# ADuCM302x register map
Vendor: Analog Devices; Series: ADuCM302x; File version: 1p0
CPU: CM3 r0p1, little endian, no MPU, no FPU, 3 interrupt priority bits
Registers are 32-bit, read-write, reset 0x0 unless marked. A register's access mark holds for its fields unless they carry their own. Offsets are from the block's base; [hi:lo] are bit positions; {n}, {i} and the like mark numbered series; <NAME> marks a mode.

## PMG0 — Power Management
Base 0x4004C000
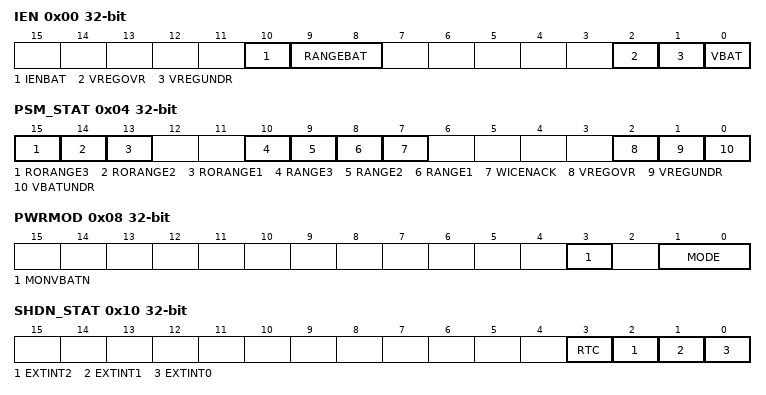
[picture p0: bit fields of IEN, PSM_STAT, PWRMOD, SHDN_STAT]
0x00 IEN — Power Supply Monitor Interrupt Enable
  [10] IENBAT range 0x00000000..0x00000001 — Interrupt Enable for VBAT Range
  [9:8] RANGEBAT — Battery Monitor Range
    0=region1 (Configure to generate interrupt if VBAT > 2.75 V); 1=region2 (Configure to generate interrupt if VBAT between 2.75 V - 1.6 V); 2=region3 (Configure to generate interrupt if VBAT between 2.3 V - 1.6 V); 3=NA
  [2] VREGOVR range 0x00000000..0x00000001 — Enable Interrupt When VREG Overvoltage: Above 1.32V
  [1] VREGUNDR range 0x00000000..0x00000001 — Enable Interrupt When VREG Undervoltage: Below 1V
  [0] VBAT range 0x00000000..0x00000001 — Enable Interrupt for VBAT
0x04 PSM_STAT — Power Supply Monitor Status
  [15] RORANGE3 ro — VBAT Range3 (2.3v - 1.6v)
  [14] RORANGE2 ro — VBAT Range2 (2.75v - 2.3v)
  [13] RORANGE1 ro — VBAT Range1 (> 2.75v)
    0=batstat1 (VBAT not in the range specified); 1=batstat0 (VBAT in the range specified)
  [10] RANGE3 — VBAT Range3 (2.3v - 1.6v)
  [9] RANGE2 — VBAT Range2 (2.75v - 2.3v)
  [8] RANGE1 — VBAT Range1 (> 2.75v)
  [7] WICENACK ro — WIC Enable Acknowledge from Cortex
  [2] VREGOVR range 0x00000000..0x00000001 — Status Bit for Alarm Indicating Overvoltage for VREG
  [1] VREGUNDR range 0x00000000..0x00000001 — Status Bit for Alarm Indicating VREG is Below 1V
  [0] VBATUNDR range 0x00000000..0x00000001 — Status Bit Indicating an Alarm That Battery is Below 1.8V
0x08 PWRMOD — Power Mode Register
  [3] MONVBATN — Monitor VBAT During Hibernate Mode. Monitors VBAT by Default
    0=VBAT_MONEN (VBAT monitor enabled in PMG block.); 1=VBAT_MONDIS (VBAT monitor disabled in PMG block.)
  [1:0] MODE — Power Mode Bits
    0=FLEXI (Flexi Mode); 2=HIBERNATE (Hibernate Mode); 3=SHUTDOWN (Shutdown Mode)
0x0C PWRKEY — Key Protection for PMG_PWRMOD and PMG_SRAMRET
  [15:0] VALUE wo range 0x00000000..0x0000FFFF — Power Control Key Register
0x10 SHDN_STAT — Shutdown Status Register
  [3] RTC ro — Wakeup by Interrupt from RTC
  [2] EXTINT2 ro — Wakeup by Interrupt from External Interrupt 2
  [1] EXTINT1 ro — Wakeup by Interrupt from External Interrupt 1
  [0] EXTINT0 ro — Wakeup by Interrupt from External Interrupt 0
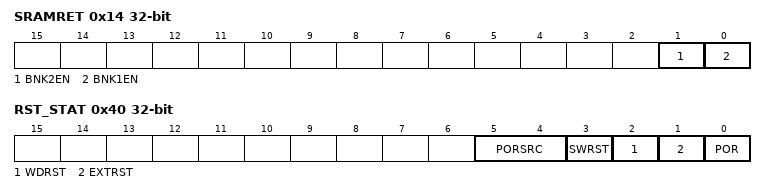
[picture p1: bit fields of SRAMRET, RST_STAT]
0x14 SRAMRET — Control for Retention SRAM in Hibernate Mode
  [1] BNK2EN range 0x00000000..0x00000001 — Enable Retention Bank 2 (16kB)
  [0] BNK1EN range 0x00000000..0x00000001 — Enable Retention Bank 1 (8kB)
0x40 RST_STAT — Reset Status
  [5:4] PORSRC ro — Power-on-Reset Source
    0=FAILSAFE_HV (POR triggered because VBAT drops below Fail Safe); 1=RST_VBAT (POR trigger because VBAT supply (VBAT < 1.7 V)); 2=RST_VREG (POR triggered because VDD supply (VDD < 1.08 V)); 3=FAILSAFE_LV (POR triggered because VREG drops below Fail Safe)
  [3] SWRST range 0x00000000..0x00000001 — Software Reset
  [2] WDRST range 0x00000000..0x00000001 — Watchdog Time-out Reset
  [1] EXTRST range 0x00000000..0x00000001 — External Reset
  [0] POR range 0x00000000..0x00000001 — Power-on-Reset
0x44 CTL1 reset 0xA00000 — HP Buck Control
  [0] HPBUCKEN range 0x00000000..0x00000001 — Enable HP Buck

## XINT0 — External interrupt configuration
Base 0x4004C080
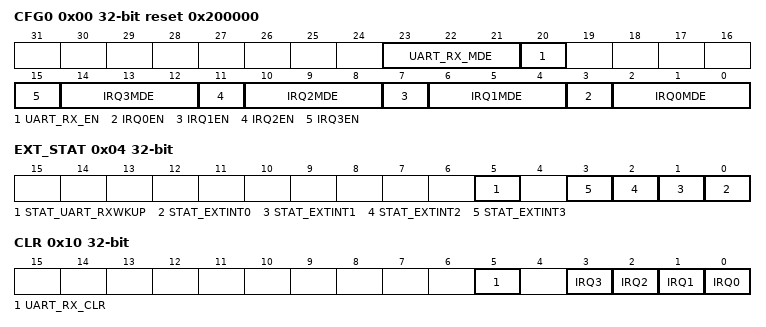
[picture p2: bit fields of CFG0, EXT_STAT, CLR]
0x00 CFG0 reset 0x200000 — External Interrupt Configuration
  [23:21] UART_RX_MDE — External Interrupt Using UART_RX Wakeup Mode Registers
  [20] UART_RX_EN — External Interrupt Enable Bit
  [4n+3] IRQ{n}EN (n=0..3) — External Interrupt {n} Enable Bit
  [4n+2:4n] IRQ{n}MDE (n=0..3) — External Interrupt {n} Mode Registers
0x04 EXT_STAT — External Wakeup Interrupt Status
  [5] STAT_UART_RXWKUP ro — Interrupt Status Bit for UART RX Wakeup Interrupt
  [n] STAT_EXTINT{n} ro (n=0..3) — Interrupt Status Bit for External Interrupt {n}
0x10 CLR — External Interrupt Clear
  [5] UART_RX_CLR range 0x00000000..0x00000001 — External Interrupt Clear for UART_RX Wakeup Interrupt
  [n] IRQ{n} range 0x00000000..0x00000001 (n=0..3) — External Interrupt {n}
0x14 NMICLR — Non-Maskable Interrupt Clear
  [0] CLR range 0x00000000..0x00000001 — NMI Clear
